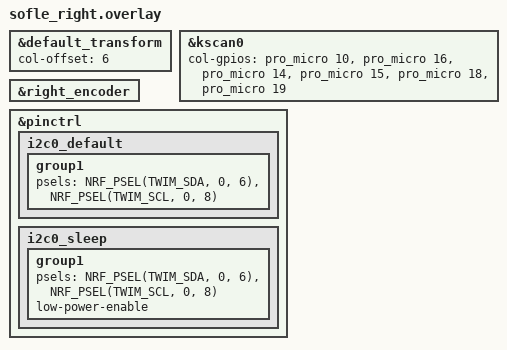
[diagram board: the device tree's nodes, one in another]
/*
 * Copyright (c) 2020 Ryan Cross
 *
 * SPDX-License-Identifier: MIT
 */

#include "sofle.dtsi"

&default_transform {
    col-offset = <6>;
};

&kscan0 {
    col-gpios
        = <&pro_micro 10 GPIO_ACTIVE_HIGH>
        , <&pro_micro 16 GPIO_ACTIVE_HIGH>
        , <&pro_micro 14 GPIO_ACTIVE_HIGH>
        , <&pro_micro 15 GPIO_ACTIVE_HIGH>
        , <&pro_micro 18 GPIO_ACTIVE_HIGH>
        , <&pro_micro 19 GPIO_ACTIVE_HIGH>
        ;
};

&right_encoder {
    status = "okay";
};

&pinctrl {
    i2c0_default: i2c0_default {
        group1 {
            psels = <NRF_PSEL(TWIM_SDA, 0, 6)>,
                    <NRF_PSEL(TWIM_SCL, 0, 8)>;
        };
    };

    i2c0_sleep: i2c0_sleep {
        group1 {
            psels = <NRF_PSEL(TWIM_SDA, 0, 6)>,
                    <NRF_PSEL(TWIM_SCL, 0, 8)>;
            low-power-enable;
        };
    };
};


